# HC32F448JATI register map
File version: 1.0
CPU: CM4 r0p1, little endian, MPU, FPU, 4 interrupt priority bits
Registers are 32-bit, read-write, reset 0x0 unless marked. A register's access mark holds for its fields unless they carry their own. Offsets are from the block's base; [hi:lo] are bit positions; {n}, {i} and the like mark numbered series.

## AES
Base 0x40008000
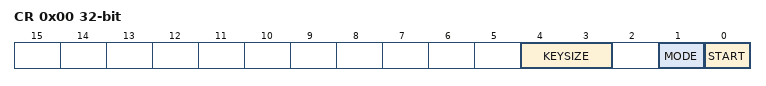
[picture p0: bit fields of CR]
0x00 CR
  [4:3] KEYSIZE, [1] MODE, [0] START
{0x10+4i} DR{i} (i=0..3)
{0x20+4i} KR{i} (i=0..7)

## AOS
Base 0x40010800
0x00 INTSFTTRG wo
  [0] STRG
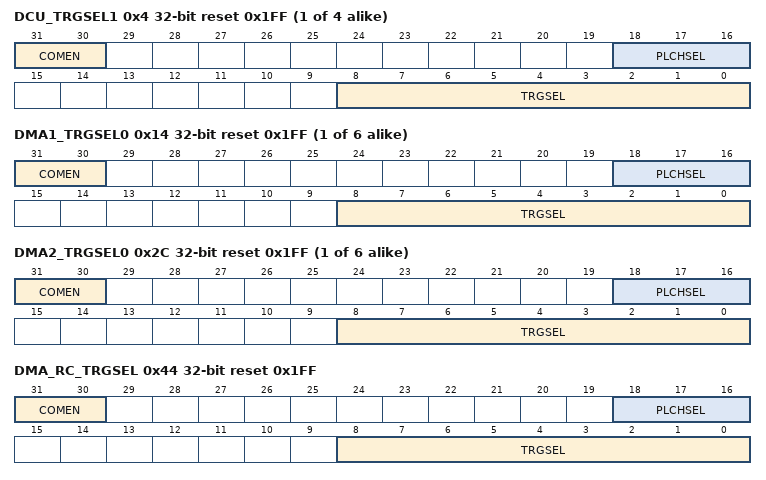
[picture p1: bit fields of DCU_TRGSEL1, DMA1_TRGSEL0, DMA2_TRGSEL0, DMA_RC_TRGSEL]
{0x0+4i} DCU_TRGSEL{i} reset 0x1FF (i=1..4)
  [31:30] COMEN, [18:16] PLCHSEL, [8:0] TRGSEL
{0x14+4i} DMA1_TRGSEL{i} reset 0x1FF (i=0..5)
  [31:30] COMEN, [18:16] PLCHSEL, [8:0] TRGSEL
{0x2C+4i} DMA2_TRGSEL{i} reset 0x1FF (i=0..5)
  [31:30] COMEN, [18:16] PLCHSEL, [8:0] TRGSEL
0x44 DMA_RC_TRGSEL reset 0x1FF
  [31:30] COMEN, [18:16] PLCHSEL, [8:0] TRGSEL
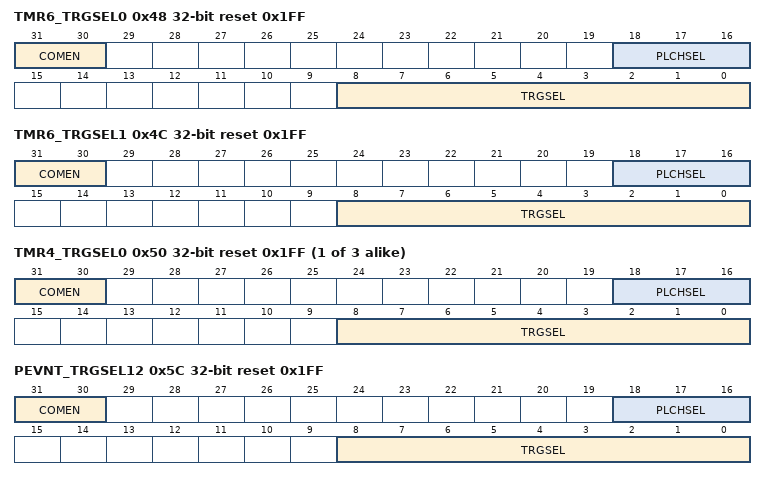
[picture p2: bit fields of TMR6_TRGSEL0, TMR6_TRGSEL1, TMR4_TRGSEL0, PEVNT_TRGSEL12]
0x48 TMR6_TRGSEL0 reset 0x1FF
  [31:30] COMEN, [18:16] PLCHSEL, [8:0] TRGSEL
0x4C TMR6_TRGSEL1 reset 0x1FF
  [31:30] COMEN, [18:16] PLCHSEL, [8:0] TRGSEL
{0x50+4i} TMR4_TRGSEL{i} reset 0x1FF (i=0..2)
  [31:30] COMEN, [18:16] PLCHSEL, [8:0] TRGSEL
0x5C PEVNT_TRGSEL12 reset 0x1FF
  [31:30] COMEN, [18:16] PLCHSEL, [8:0] TRGSEL
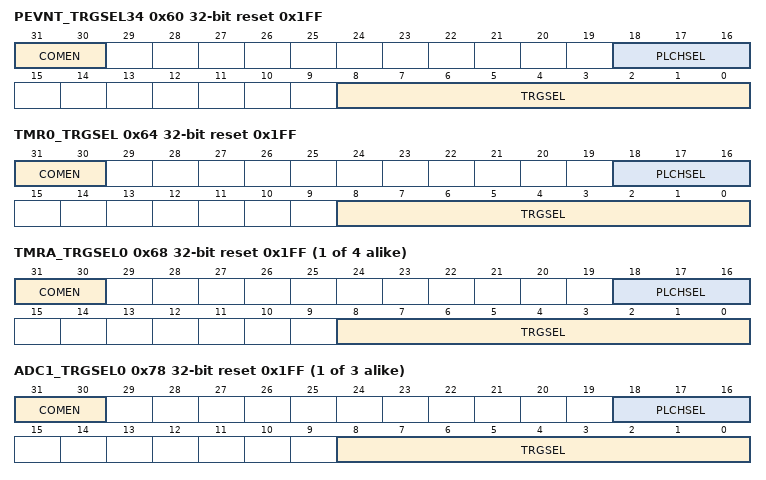
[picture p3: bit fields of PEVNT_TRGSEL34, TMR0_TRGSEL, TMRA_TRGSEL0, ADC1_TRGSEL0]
0x60 PEVNT_TRGSEL34 reset 0x1FF
  [31:30] COMEN, [18:16] PLCHSEL, [8:0] TRGSEL
0x64 TMR0_TRGSEL reset 0x1FF
  [31:30] COMEN, [18:16] PLCHSEL, [8:0] TRGSEL
{0x68+4i} TMRA_TRGSEL{i} reset 0x1FF (i=0..3)
  [31:30] COMEN, [18:16] PLCHSEL, [8:0] TRGSEL
{0x70+8i} ADC{i}_TRGSEL0 reset 0x1FF (i=1..3)
  [31:30] COMEN, [18:16] PLCHSEL, [8:0] TRGSEL
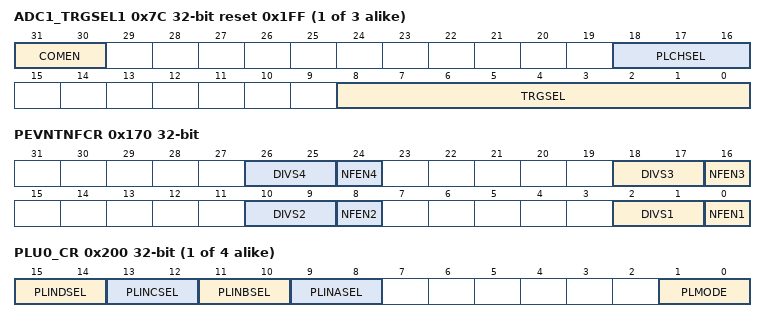
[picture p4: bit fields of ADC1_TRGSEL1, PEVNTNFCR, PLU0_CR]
{0x74+8i} ADC{i}_TRGSEL1 reset 0x1FF (i=1..3)
  [31:30] COMEN, [18:16] PLCHSEL, [8:0] TRGSEL
0x90 COMTRGSEL1 reset 0x1FF
  [8:0] TRGSEL
0x94 COMTRGSEL2 reset 0x1FF
  [8:0] TRGSEL
{0xE4+0x1C*i} PEVNTDIRR{i} (i=1..4)
  [15:0] PDIR
{0xE8+0x1C*i} PEVNTIDR{i} ro (i=1..4)
  [15:0] PIN
{0xEC+0x1C*i} PEVNTODR{i} (i=1..4)
  [15:0] POUT
{0xF0+0x1C*i} PEVNTORR{i} (i=1..4)
  [15:0] POR
{0xF4+0x1C*i} PEVNTOSR{i} (i=1..4)
  [15:0] POS
{0xF8+0x1C*i} PEVNTRISR{i} (i=1..4)
  [15:0] RIS
{0xFC+0x1C*i} PEVNTFALR{i} (i=1..4)
  [15:0] FAL
0x170 PEVNTNFCR
  [8n-6:8n-7] DIVS{n} (n=1..4), [8n-8] NFEN{n} (n=1..4)
{0x200+4i} PLU{i}_CR (i=0..3)
  [15:14] PLINDSEL, [13:12] PLINCSEL, [11:10] PLINBSEL, [9:8] PLINASEL, [1:0] PLMODE
{0x210+0x10*i} PLU{i}_TRGSELA reset 0x1FF (i=0..3)
  [8:0] PLTRGSEL
{0x214+0x10*i} PLU{i}_TRGSELB reset 0x1FF (i=0..3)
  [8:0] PLTRGSEL
{0x218+0x10*i} PLU{i}_TRGSELC reset 0x1FF (i=0..3)
  [8:0] PLTRGSEL
{0x21C+0x10*i} PLU{i}_TRGSELD reset 0x1FF (i=0..3)
  [8:0] PLTRGSEL

## CMP1
Base 0x40038800
Same registers: CMP3 0x40038C00
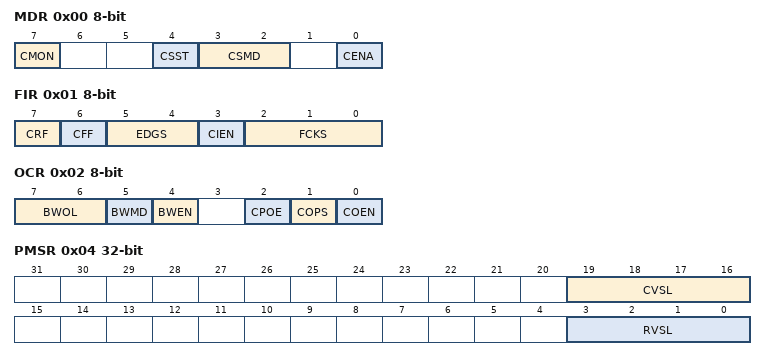
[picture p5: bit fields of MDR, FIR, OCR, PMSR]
0x00 MDR 8-bit
  [7] CMON ro, [4] CSST, [3:2] CSMD, [0] CENA
0x01 FIR 8-bit
  [7] CRF, [6] CFF, [5:4] EDGS, [3] CIEN, [2:0] FCKS
0x02 OCR 8-bit
  [7:6] BWOL, [5] BWMD, [4] BWEN, [2] CPOE, [1] COPS, [0] COEN
0x04 PMSR
  [19:16] CVSL, [3:0] RVSL
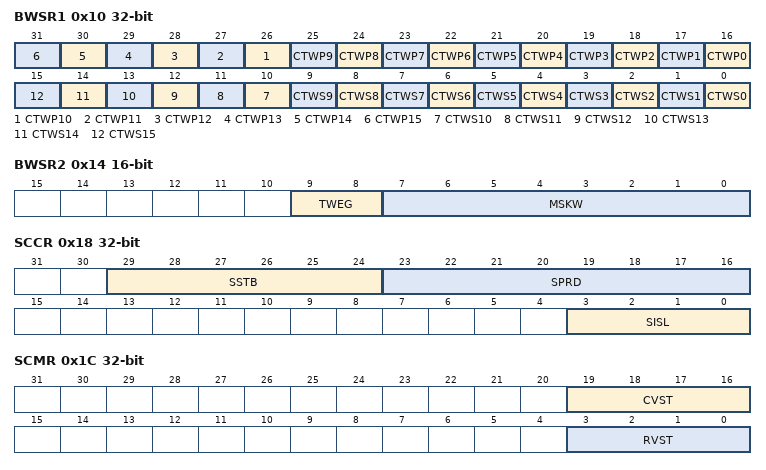
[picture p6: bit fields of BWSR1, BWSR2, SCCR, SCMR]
0x10 BWSR1
  [n+16] CTWP{n} (n=0..15), [n] CTWS{n} (n=0..15)
0x14 BWSR2 16-bit
  [9:8] TWEG, [7:0] MSKW
0x18 SCCR
  [29:24] SSTB, [23:16] SPRD, [3:0] SISL
0x1C SCMR
  [19:16] CVST, [3:0] RVST

## CMP2
Base 0x40038900
Same registers: CMP4 0x40038D00
Registers as CMP1; these are added or differ:
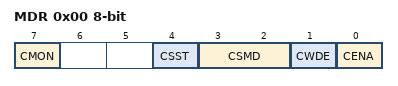
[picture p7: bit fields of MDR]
0x00 MDR 8-bit
  [7] CMON ro, [4] CSST, [3:2] CSMD, [1] CWDE, [0] CENA

## CMU
Base 0x40048000
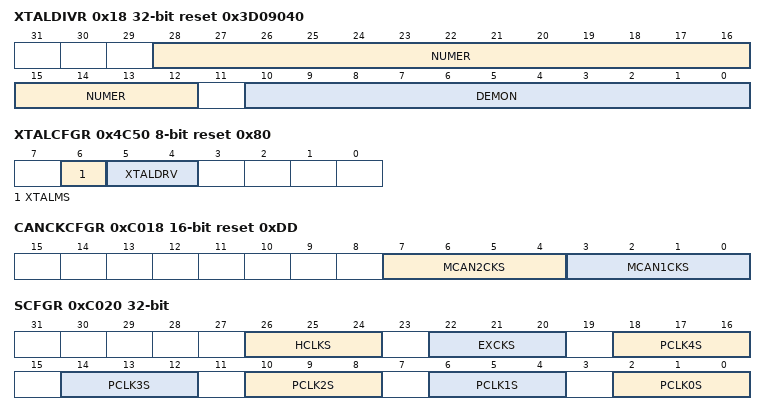
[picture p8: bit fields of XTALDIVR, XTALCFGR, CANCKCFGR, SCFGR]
0x18 XTALDIVR reset 0x3D09040
  [28:12] NUMER, [10:0] DEMON
0x1C XTALDIVCR
  [0] FRADIVEN
0x4C50 XTALCFGR 8-bit reset 0x80
  [6] XTALMS, [5:4] XTALDRV
0x4C54 XTAL32CR 8-bit
  [0] XTAL32STP
0x4C58 XTAL32CFGR 8-bit
  [2:0] XTAL32DRV
0x4C68 XTAL32NFR 8-bit
  [1:0] XTAL32NF
0x4C6C LRCCR 8-bit
  [0] LRCSTP
0x4C74 LRCTRM 8-bit
0xC010 PERICKSEL 16-bit
  [3:0] PERICKSEL
0xC018 CANCKCFGR 16-bit reset 0xDD
  [7:4] MCAN2CKS, [3:0] MCAN1CKS
0xC020 SCFGR
  [26:24] HCLKS, [22:20] EXCKS, [4n+2:4n] PCLK{n}S (n=0..4)
0xC026 CKSWR 8-bit reset 0x1
  [2:0] CKSW
0xC02A PLLHCR 8-bit reset 0x1
  [0] PLLHOFF
0xC032 XTALCR 8-bit reset 0x1
  [0] XTALSTP
0xC036 HRCCR 8-bit reset 0x1
  [0] HRCSTP
0xC038 MRCCR 8-bit reset 0x80
  [0] MRCSTP
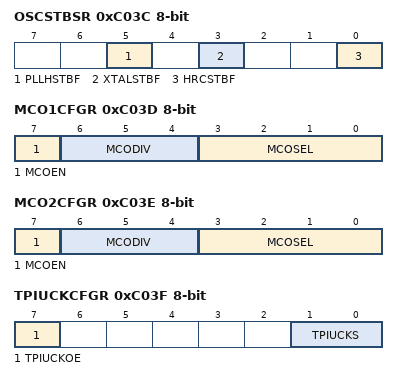
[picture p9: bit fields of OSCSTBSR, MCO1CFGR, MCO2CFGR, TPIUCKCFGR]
0xC03C OSCSTBSR 8-bit
  [5] PLLHSTBF, [3] XTALSTBF, [0] HRCSTBF
0xC03D MCO1CFGR 8-bit
  [7] MCOEN, [6:4] MCODIV, [3:0] MCOSEL
0xC03E MCO2CFGR 8-bit
  [7] MCOEN, [6:4] MCODIV, [3:0] MCOSEL
0xC03F TPIUCKCFGR 8-bit
  [7] TPIUCKOE, [1:0] TPIUCKS
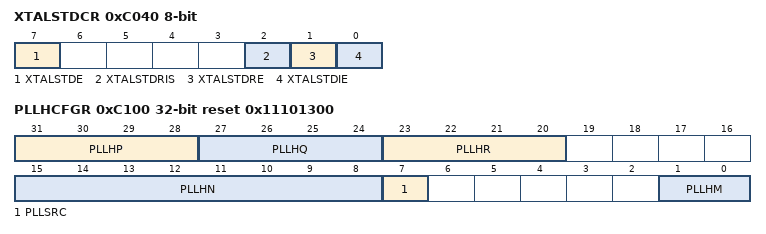
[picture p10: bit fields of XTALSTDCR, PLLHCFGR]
0xC040 XTALSTDCR 8-bit
  [7] XTALSTDE, [2] XTALSTDRIS, [1] XTALSTDRE, [0] XTALSTDIE
0xC041 XTALSTDSR 8-bit
  [0] XTALSTDF
0xC061 MRCTRM 8-bit
0xC062 HRCTRM 8-bit
0xC0A2 XTALSTBCR 8-bit reset 0x5
  [3:0] XTALSTB
0xC100 PLLHCFGR reset 0x11101300
  [31:28] PLLHP, [27:24] PLLHQ, [23:20] PLLHR, [15:8] PLLHN, [7] PLLSRC, [1:0] PLLHM
